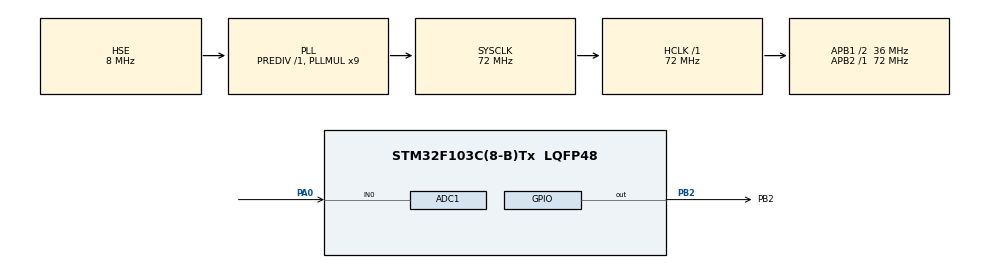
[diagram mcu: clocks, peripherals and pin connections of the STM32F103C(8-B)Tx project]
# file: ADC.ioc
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ADC1.Channel-2\#ChannelRegularConversion=ADC_CHANNEL_0
ADC1.ContinuousConvMode=ENABLE
ADC1.DiscontinuousConvMode=DISABLE
ADC1.NbrOfConversion=1
ADC1.NbrOfConversionFlag=1
ADC1.Rank-2\#ChannelRegularConversion=1
ADC1.SamplingTime-2\#ChannelRegularConversion=ADC_SAMPLETIME_41CYCLES_5
ADC1.master=1
Dma.ADC1.0.Direction=DMA_PERIPH_TO_MEMORY
Dma.ADC1.0.Instance=DMA1_Channel1
Dma.ADC1.0.MemDataAlignment=DMA_MDATAALIGN_HALFWORD
Dma.ADC1.0.MemInc=DMA_MINC_ENABLE
Dma.ADC1.0.Mode=DMA_CIRCULAR
Dma.ADC1.0.PeriphDataAlignment=DMA_PDATAALIGN_HALFWORD
Dma.ADC1.0.PeriphInc=DMA_PINC_DISABLE
Dma.ADC1.0.Priority=DMA_PRIORITY_MEDIUM
Dma.Request0=ADC1
Mcu.Family=STM32F1
Mcu.Name=STM32F103C(8-B)Tx
Mcu.Package=LQFP48
NVIC.ADC1_2_IRQn=true\:0\:0\:false\:false\:true\:true\:true
NVIC.DMA1_Channel1_IRQn=true\:0\:0\:false\:false\:true\:false\:true
NVIC.PriorityGroup=NVIC_PRIORITYGROUP_4
PA0-WKUP.Signal=ADCx_IN0
PA13.Mode=Serial_Wire
PA13.Signal=SYS_JTMS-SWDIO
PA14.Mode=Serial_Wire
PA14.Signal=SYS_JTCK-SWCLK
PB2.GPIO_Label=PB2
PB2.PinState=GPIO_PIN_RESET
PB2.Signal=GPIO_Output
PD0-OSC_IN.Mode=HSE-External-Oscillator
PD0-OSC_IN.Signal=RCC_OSC_IN
PD1-OSC_OUT.Mode=HSE-External-Oscillator
PD1-OSC_OUT.Signal=RCC_OSC_OUT
ProjectManager.HeapSize=0x200
ProjectManager.StackSize=0x400
ProjectManager.TargetToolchain=MDK-ARM V5.27
RCC.ADCPresc=RCC_ADCPCLK2_DIV6
RCC.AHBFreq_Value=72000000
RCC.APB1CLKDivider=RCC_HCLK_DIV2
RCC.APB1Freq_Value=36000000
RCC.APB1TimFreq_Value=72000000
RCC.APB2Freq_Value=72000000
RCC.APB2TimFreq_Value=72000000
RCC.HCLKFreq_Value=72000000
RCC.PLLMUL=RCC_PLL_MUL9
RCC.PLLSourceVirtual=RCC_PLLSOURCE_HSE
RCC.SYSCLKFreq_VALUE=72000000
RCC.SYSCLKSource=RCC_SYSCLKSOURCE_PLLCLK
RCC.USBFreq_Value=72000000
SH.ADCx_IN0.0=ADC1_IN0,IN0
board=custom

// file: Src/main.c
/* USER CODE BEGIN Header */
/**
  ******************************************************************************
  * @file           : main.c
  * @brief          : Main program body
  ******************************************************************************
  * @attention
  *
  * <h2><center>&copy; Copyright (c) 2020 STMicroelectronics.
  * All rights reserved.</center></h2>
  *
  * This software component is licensed by ST under BSD 3-Clause license,
  * the "License"; You may not use this file except in compliance with the
  * License. You may obtain a copy of the License at:
  *                        opensource.org/licenses/BSD-3-Clause
  *
  ******************************************************************************
  */
/* USER CODE END Header */

#include "main.h"
#include "adc.h"
#include "dma.h"
#include "gpio.h"

/* USER CODE BEGIN PV */
uint16_t uadc0;
uint32_t voltage0= 0;
/* USER CODE END PV */

void SystemClock_Config(void);

/* USER CODE BEGIN 0 */
void LED_Blink(uint32_t delay)
{
	HAL_GPIO_WritePin(PB2_GPIO_Port,PB2_Pin,GPIO_PIN_SET);
	HAL_Delay(delay - 1);
	HAL_GPIO_WritePin(PB2_GPIO_Port,PB2_Pin,GPIO_PIN_RESET);
	if(voltage0 < 3000) // PA0 ADC1_IN0 < 3000mV
		HAL_Delay(500-1);
	else
		HAL_Delay(100-1);
}
void HAL_ADC_ConvCpltCallback(ADC_HandleTypeDef* hadc)
{

}

 /*
  *power by WeAct Studio
  *The board with `WeAct` Logo && `version number` is our board, quality guarantee.
  *For more information please visit: https://github.com/WeActStudio/BluePill-Plus.git
  *更多信息请访问：https://gitee.com/WeActStudio/BluePill-Plus
  */

/* USER CODE END 0 */

int main(void)
{

  /* MCU Configuration--------------------------------------------------------*/

  /* Reset of all peripherals, Initializes the Flash interface and the Systick. */
  HAL_Init();

  /* Configure the system clock */
  SystemClock_Config();

  /* Initialize all configured peripherals */
  MX_GPIO_Init();
  MX_DMA_Init();
  MX_ADC1_Init();
  /* USER CODE BEGIN 2 */
	/* Run the ADC calibration */
  if (HAL_ADCEx_Calibration_Start(&hadc1) != HAL_OK)
  {
    /* Calibration Error */
    Error_Handler();
  }

  HAL_ADC_Start_DMA(&hadc1,(uint32_t *)&uadc0,1);
  /* USER CODE END 2 */

  /* Infinite loop */
  while (1)
  {

    /* USER CODE BEGIN 3 */
		voltage0 = (uint32_t)(uadc0*3300 >> 12);
		LED_Blink(5);
  }
  /* USER CODE END 3 */
}

void SystemClock_Config(void)
{
  RCC_OscInitTypeDef RCC_OscInitStruct = {0};
  RCC_ClkInitTypeDef RCC_ClkInitStruct = {0};
  RCC_PeriphCLKInitTypeDef PeriphClkInit = {0};

  /** Initializes the CPU, AHB and APB busses clocks
  */
  RCC_OscInitStruct.OscillatorType = RCC_OSCILLATORTYPE_HSE;
  RCC_OscInitStruct.HSEState = RCC_HSE_ON;
  RCC_OscInitStruct.HSEPredivValue = RCC_HSE_PREDIV_DIV1;
  RCC_OscInitStruct.HSIState = RCC_HSI_ON;
  RCC_OscInitStruct.PLL.PLLState = RCC_PLL_ON;
  RCC_OscInitStruct.PLL.PLLSource = RCC_PLLSOURCE_HSE;
  RCC_OscInitStruct.PLL.PLLMUL = RCC_PLL_MUL9;
  if (HAL_RCC_OscConfig(&RCC_OscInitStruct) != HAL_OK)
  {
    Error_Handler();
  }
  /** Initializes the CPU, AHB and APB busses clocks
  */
  RCC_ClkInitStruct.ClockType = RCC_CLOCKTYPE_HCLK|RCC_CLOCKTYPE_SYSCLK
                              |RCC_CLOCKTYPE_PCLK1|RCC_CLOCKTYPE_PCLK2;
  RCC_ClkInitStruct.SYSCLKSource = RCC_SYSCLKSOURCE_PLLCLK;
  RCC_ClkInitStruct.AHBCLKDivider = RCC_SYSCLK_DIV1;
  RCC_ClkInitStruct.APB1CLKDivider = RCC_HCLK_DIV2;
  RCC_ClkInitStruct.APB2CLKDivider = RCC_HCLK_DIV1;

  if (HAL_RCC_ClockConfig(&RCC_ClkInitStruct, FLASH_LATENCY_2) != HAL_OK)
  {
    Error_Handler();
  }
  PeriphClkInit.PeriphClockSelection = RCC_PERIPHCLK_ADC;
  PeriphClkInit.AdcClockSelection = RCC_ADCPCLK2_DIV6;
  if (HAL_RCCEx_PeriphCLKConfig(&PeriphClkInit) != HAL_OK)
  {
    Error_Handler();
  }
}

void Error_Handler(void)
{
  /* USER CODE BEGIN Error_Handler_Debug */
  /* User can add his own implementation to report the HAL error return state */
	while(1)
	{
   HAL_GPIO_TogglePin(PB2_GPIO_Port,PB2_Pin);
	 HAL_Delay(100);
	}
  /* USER CODE END Error_Handler_Debug */
}

/************************ (C) COPYRIGHT STMicroelectronics *****END OF FILE****/
